# nrf9120_MLM1 register map
Vendor: Nordic Semiconductor; Series: nrf91; File version: 1
CPU: CM4 r0p1, little endian, MPU, FPU, 3 interrupt priority bits
Registers are 32-bit, read-write, reset 0x0 unless marked. A register's access mark holds for its fields unless they carry their own. Offsets are from the block's base; [hi:lo] are bit positions; lines under a group give offsets from that group; {n}, {i} and the like mark numbered series.

## VMC — Volatile Memory controller
Base 0x40031000
{0x600+0x10*i} RAM[{i}] (i=0..7) group — Unspecified
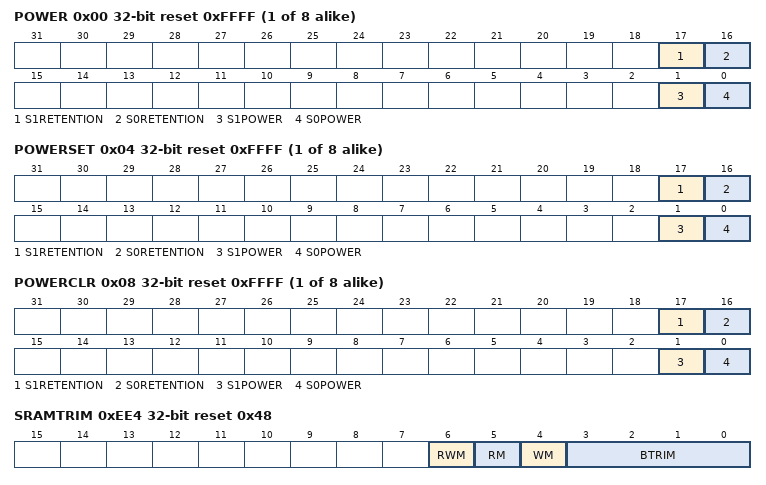
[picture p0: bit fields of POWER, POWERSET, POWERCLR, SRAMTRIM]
  0x00 POWER reset 0xFFFF — Description cluster[0]: RAM0 power control register
    [all] fields
      0=Off; 1=On
    [17] S1RETENTION — Keep retention on RAM section S1 of RAM 0 when RAM section is switched off
    [16] S0RETENTION — Keep retention on RAM section S0 of RAM 0 when RAM section is switched off
    [1] S1POWER — Keep RAM section S1 of RAM 0 on or off in System ON mode
    [0] S0POWER — Keep RAM section S0 of RAM 0 on or off in System ON mode
  0x04 POWERSET wo reset 0xFFFF — Description cluster[0]: RAM0 power control set register
    [all] fields
      1=On
    [17] S1RETENTION — Keep retention on RAM section S1 of RAM 0 when RAM section is switched off
    [16] S0RETENTION — Keep retention on RAM section S0 of RAM 0 when RAM section is switched off
    [1] S1POWER — Keep RAM section S1 of RAM 0 on or off in System ON mode
    [0] S0POWER — Keep RAM section S0 of RAM 0 on or off in System ON mode
  0x08 POWERCLR wo reset 0xFFFF — Description cluster[0]: RAM0 power control clear register
    [all] fields
      1=Off
    [17] S1RETENTION — Keep retention on RAM section S1 of RAM 0 when RAM section is switched off
    [16] S0RETENTION — Keep retention on RAM section S0 of RAM 0 when RAM section is switched off
    [1] S1POWER — Keep RAM section S1 of RAM 0 on or off in System ON mode
    [0] S0POWER — Keep RAM section S0 of RAM 0 on or off in System ON mode
  0x0C UNUSED0 — Unspecified
0xEE4 SRAMTRIM reset 0x48 — Backdoor trim values for SRAM
  [6] RWM — Read/Write Margin Adjustment
    0=Disabled; 1=Enabled
  [5] RM — Read Margin Adjustment
    0=Disabled; 1=Enabled
  [4] WM — Write Margin Adjustment
    0=Disabled; 1=Enabled
  [3:0] BTRIM — Source Bias Trim Adjustment for retention
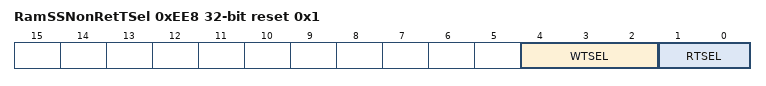
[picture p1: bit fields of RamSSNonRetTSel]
0xEE8 RamSSNonRetTSel reset 0x1 — Timing control values for TSMC RAMs
  [4:2] WTSEL — Write cycle timing selection
  [1:0] RTSEL — Read cycle timing selection

## GPIO — GPIO Port
Base 0x40800000
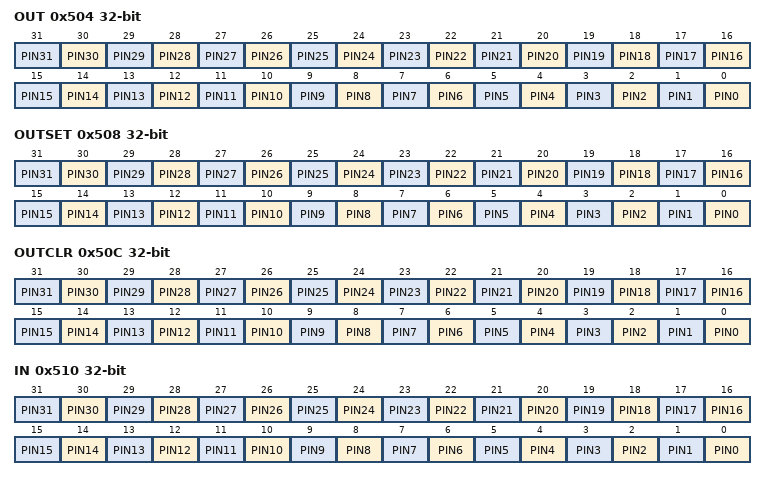
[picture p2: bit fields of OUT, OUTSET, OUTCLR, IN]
0x504 OUT — Write GPIO port
  [all] fields
    0=Low (Pin driver is low); 1=High (Pin driver is high)
  [n] PIN{n} (n=0..31)
0x508 OUTSET write-1-sets — Set individual bits in GPIO port
  [all] fields
    on read: 0=Low (Read: pin driver is low); 1=High (Read: pin driver is high) | on write: 1=Set (Write: writing a '1' sets the pin high; writing a '0' has no effect)
  [n] PIN{n} (n=0..31)
0x50C OUTCLR write-1-clears — Clear individual bits in GPIO port
  [all] fields
    on read: 0=Low (Read: pin driver is low); 1=High (Read: pin driver is high) | on write: 1=Clear (Write: writing a '1' sets the pin low; writing a '0' has no effect)
  [n] PIN{n} (n=0..31)
0x510 IN ro — Read GPIO port
  [all] fields
    0=Low (Pin input is low); 1=High (Pin input is high)
  [n] PIN{n} (n=0..31)
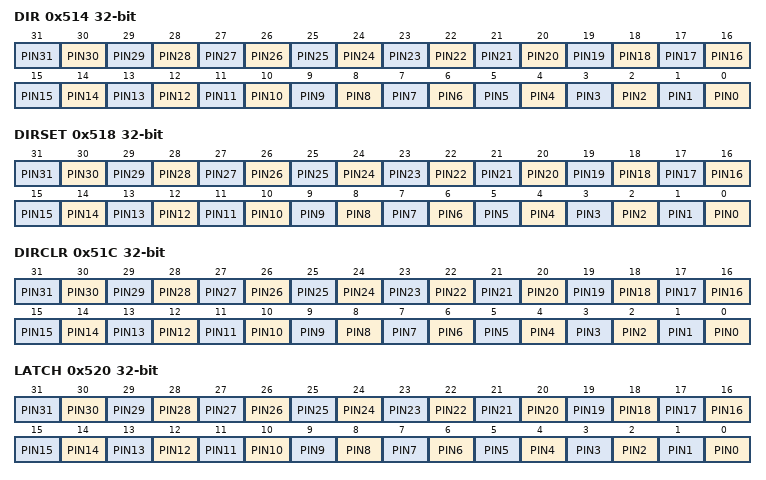
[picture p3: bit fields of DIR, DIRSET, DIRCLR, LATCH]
0x514 DIR — Direction of GPIO pins
  [all] fields
    0=Input (Pin set as input); 1=Output (Pin set as output)
  [n] PIN{n} (n=0..31)
0x518 DIRSET write-1-sets
  [all] fields
    on read: 0=Input (Read: pin set as input); 1=Output (Read: pin set as output) | on write: 1=Set (Write: writing a '1' sets pin to output; writing a '0' has no effect)
  [n] PIN{n} (n=0..31) — Set as output pin {n}
0x51C DIRCLR write-1-clears — DIR clear register
  [all] fields
    on read: 0=Input (Read: pin set as input); 1=Output (Read: pin set as output) | on write: 1=Clear (Write: writing a '1' sets pin to input; writing a '0' has no effect)
  [n] PIN{n} (n=0..31) — Set as input pin {n}
0x520 LATCH — Latch register indicating what GPIO pins that have met the criteria set in the PIN_CNF[n].SENSE registers
  [all] fields
    0=NotLatched (Criteria has not been met); 1=Latched (Criteria has been met)
  [n] PIN{n} (n=0..31) — Status on whether PIN{n} has met criteria set in PIN_CNF{n}.SENSE register. Write '1' to clear.
0x524 DETECTMODE — Select between default DETECT signal behaviour and LDETECT mode
  [0] DETECTMODE
    0=Default (DETECT directly connected to PIN DETECT signals); 1=LDETECT (Use the latched LDETECT behaviour)
{0x600+8i} PIN[{i}] (i=0..31) group — Pin 0 direct access
  0x00 OUT — Description cluster[0]: Pin 0 direct access output register
    [0] OUT — Direct access
  0x04 IN — Description cluster[0]: Pin 0 direct access input register
    [0] IN — Direct access
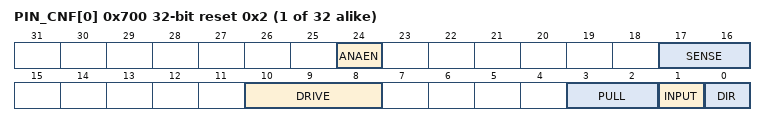
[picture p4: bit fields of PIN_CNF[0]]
{0x700+4i} PIN_CNF[{i}] (i=0..31) reset 0x2 — Description collection[0]: Configuration of GPIO pins
  [24] ANAEN — Override of analog mux enable signals for pads with analog functionality
    0=Disabled (Override of analog mux is disabled); 1=AE0 (Enable analog signal 0 (analog test bus))
  [17:16] SENSE — Pin sensing mechanism
    0=Disabled; 2=High (Sense for high level); 3=Low (Sense for low level)
  [10:8] DRIVE — Drive configuration
    0=S0S1 (Standard '0', standard '1'); 1=H0S1 (High drive '0', standard '1'); 2=S0H1 (Standard '0', high drive '1'); 3=H0H1 (High drive '0', high 'drive '1''); 4=D0S1 (Disconnect '0' standard '1' (normally used for wired-or connections)); 5=D0H1 (Disconnect '0', high drive '1' (normally used for wired-or connections)); 6=S0D1 (Standard '0'. disconnect '1' (normally used for wired-and connections)); 7=H0D1 (High drive '0', disconnect '1' (normally used for wired-and connections))
  [3:2] PULL — Pull configuration
    0=Disabled (No pull); 1=Pull down on pin; 3=Pull up on pin
  [1] INPUT — Connect or disconnect input buffer
    0=Connect input buffer; 1=Disconnect input buffer
  [0] DIR — Pin direction. Same physical register as DIR register
    0=Input (Configure pin as an input pin); 1=Output (Configure pin as an output pin)
